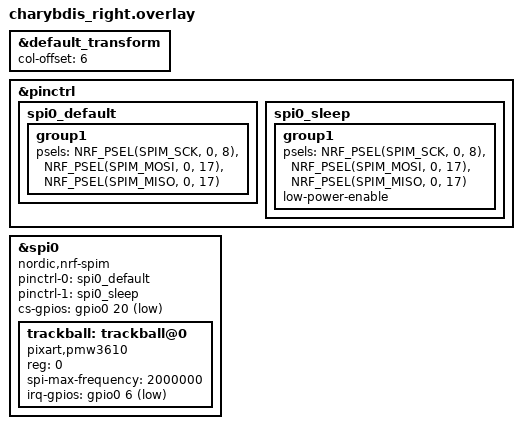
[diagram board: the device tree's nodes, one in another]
/* Charybdis right overlay - cleaned (single include, corrected SPI for 3-wire) */
#include "charybdis.dtsi"

&default_transform { col-offset = <6>; };

/*
 * Trackball bus: PMW3610 uses 3-wire SPI (MISO = MOSI per reference design).
 * Reference overlay explicitly sets miso-pin = <17> (same as mosi-pin).
 */
&pinctrl {
    spi0_default: spi0_default {
        group1 {
            psels = <NRF_PSEL(SPIM_SCK, 0, 8)>,
                    <NRF_PSEL(SPIM_MOSI, 0, 17)>,
                    <NRF_PSEL(SPIM_MISO, 0, 17)>; /* 3-wire: MISO = MOSI */
        };
    };
    spi0_sleep: spi0_sleep {
        group1 {
            psels = <NRF_PSEL(SPIM_SCK, 0, 8)>,
                    <NRF_PSEL(SPIM_MOSI, 0, 17)>,
                    <NRF_PSEL(SPIM_MISO, 0, 17)>; /* 3-wire: MISO = MOSI */
            low-power-enable;
        };
    };
};

&spi0 {
    status = "okay";
    compatible = "nordic,nrf-spim";
    pinctrl-0 = <&spi0_default>;
    pinctrl-1 = <&spi0_sleep>;
    pinctrl-names = "default", "sleep";
    cs-gpios = <&gpio0 20 GPIO_ACTIVE_LOW>;

    trackball: trackball@0 {
        compatible = "pixart,pmw3610";
        reg = <0>;
        spi-max-frequency = <2000000>; /* 2MHz */
        irq-gpios = <&gpio0 6 (GPIO_ACTIVE_LOW | GPIO_PULL_UP)>;
        status = "okay"; /* directly enabled */
    };
};

#include "charybdis_pointer.dtsi"
